AUTOSAR XML (schema 4-3-0)
package /SeatHeater
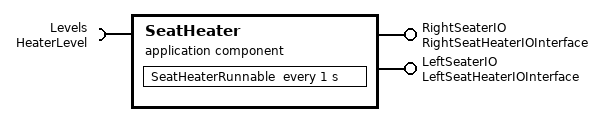
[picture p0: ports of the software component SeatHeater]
  application sw component type SeatHeater
    require port Levels: required-com-specs=[RightHeatLevel, LeftHeatLevel], required-interface=HeaterLevel
    provide port RightSeaterIO: nonqueued-sender-com-spec=RightHeaterValue, provided-interface=RightSeatHeaterIOInterface
    provide port LeftSeaterIO: nonqueued-sender-com-spec=LeftHeaterValue, provided-interface=LeftSeatHeaterIOInterface
    behavior SeatHeater_InternalBehavior
      events:
        timing event SeatHeaterEvent: start-on-event=SeatHeaterRunnable, period=1
      runnable SeatHeaterRunnable
        data-send-points:
          access SeatHeaterRightIOAccess: accessed-variable=RightSeaterIO.RightHeaterValue
          access SeatHeaterLeftIOAccess: accessed-variable=LeftSeaterIO.LeftHeaterValue
        data-receive-point-by-values:
          access SeatHeaterRightLevelAccess: accessed-variable=Levels.RightHeatLevel
          access SeatHeaterLeftLevelAccess: accessed-variable=Levels.LeftHeatLevel
  swc implementation SeatHeater_Implementation: behavior=SeatHeater_InternalBehavior
